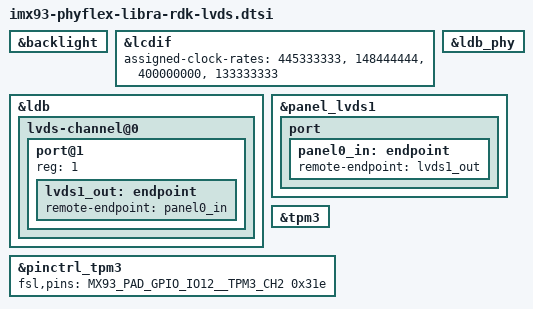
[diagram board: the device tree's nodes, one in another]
// SPDX-License-Identifier: (GPL-2.0-or-later OR MIT)
/*
 * Copyright (C) 2026 PHYTEC Messtechnik GmbH
 */

#include "imx93-pinfunc.h"

/dts-v1/;
/plugin/;

&backlight {
	status = "okay";
};

&lcdif {
	assigned-clock-rates = <445333333>, <148444444>, <400000000>, <133333333>;
	status = "okay";
};

&ldb {
	status = "okay";

	lvds-channel@0 {
		#address-cells = <1>;
		#size-cells = <0>;
		status = "okay";

		port@1 {
			reg = <1>;
			lvds1_out: endpoint {
				remote-endpoint = <&panel0_in>;
			};
		};
	};
};

&ldb_phy {
	status = "okay";
};

&panel_lvds1 {
	/* compatible panel in overlay */
	port {
		panel0_in: endpoint {
			remote-endpoint = <&lvds1_out>;
		};
	};
};

&tpm3 {
	status = "okay";
};

/* activate pull up */
&pinctrl_tpm3 {
	fsl,pins = <
		MX93_PAD_GPIO_IO12__TPM3_CH2     0x31e   /* PWM1 */
	>;
};
